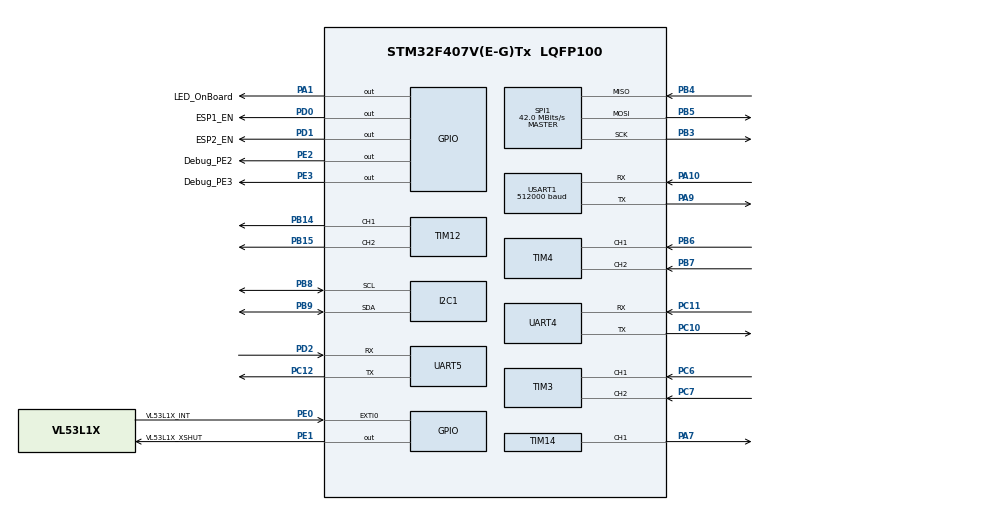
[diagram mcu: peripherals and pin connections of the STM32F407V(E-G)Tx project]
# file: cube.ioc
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ADC1.Channel-1\#ChannelRegularConversion=ADC_CHANNEL_TEMPSENSOR
ADC1.NbrOfConversionFlag=1
ADC1.Rank-1\#ChannelRegularConversion=1
ADC1.SamplingTime-1\#ChannelRegularConversion=ADC_SAMPLETIME_3CYCLES
ADC1.master=1
Dma.Request0=USART1_TX
Dma.USART1_TX.0.Direction=DMA_MEMORY_TO_PERIPH
Dma.USART1_TX.0.FIFOMode=DMA_FIFOMODE_DISABLE
Dma.USART1_TX.0.Instance=DMA2_Stream7
Dma.USART1_TX.0.MemDataAlignment=DMA_MDATAALIGN_BYTE
Dma.USART1_TX.0.MemInc=DMA_MINC_ENABLE
Dma.USART1_TX.0.Mode=DMA_NORMAL
Dma.USART1_TX.0.PeriphDataAlignment=DMA_PDATAALIGN_BYTE
Dma.USART1_TX.0.PeriphInc=DMA_PINC_DISABLE
Dma.USART1_TX.0.Priority=DMA_PRIORITY_LOW
FREERTOS.INCLUDE_pcTaskGetTaskName=1
FREERTOS.INCLUDE_xTaskGetHandle=1
FREERTOS.Tasks01=defaultTask,24,128,StartDefaultTask,Default,NULL
FREERTOS.configCHECK_FOR_STACK_OVERFLOW=2
FREERTOS.configGENERATE_RUN_TIME_STATS=1
FREERTOS.configLIBRARY_MAX_SYSCALL_INTERRUPT_PRIORITY=5
FREERTOS.configTICK_RATE_HZ=100
FREERTOS.configUSE_DAEMON_TASK_STARTUP_HOOK=1
FREERTOS.configUSE_MALLOC_FAILED_HOOK=1
Mcu.Family=STM32F4
Mcu.Name=STM32F407V(E-G)Tx
Mcu.Package=LQFP100
NVIC.DMA2_Stream7_IRQn=true\:10\:0\:true\:false\:true\:true\:false\:true
NVIC.EXTI0_IRQn=true\:10\:0\:true\:false\:true\:true\:true\:true
NVIC.I2C1_ER_IRQn=true\:10\:0\:true\:false\:true\:true\:true\:true
NVIC.I2C1_EV_IRQn=true\:10\:0\:true\:false\:true\:true\:true\:true
NVIC.PriorityGroup=NVIC_PRIORITYGROUP_4
NVIC.SPI1_IRQn=true\:10\:0\:true\:false\:true\:true\:true\:true
NVIC.TIM7_IRQn=true\:8\:0\:true\:false\:true\:true\:true\:true
NVIC.UART4_IRQn=true\:5\:0\:false\:false\:true\:true\:true\:true
NVIC.UART5_IRQn=true\:5\:0\:false\:false\:true\:true\:true\:true
NVIC.USART1_IRQn=true\:10\:0\:true\:false\:true\:true\:true\:true
PA1.GPIO_Label=LED_OnBoard
PA1.Signal=GPIO_Output
PA10.Mode=Asynchronous
PA10.Signal=USART1_RX
PA13.Mode=Serial_Wire
PA13.Signal=SYS_JTMS-SWDIO
PA14.Mode=Serial_Wire
PA14.Signal=SYS_JTCK-SWCLK
PA15.GPIO_Label=SPI_Flash_NCS
PA15.Signal=SPI1_NSS
PA7.Signal=S_TIM14_CH1
PA9.Mode=Asynchronous
PA9.Signal=USART1_TX
PB14.Signal=S_TIM12_CH1
PB15.Signal=S_TIM12_CH2
PB3.Mode=Full_Duplex_Master
PB3.Signal=SPI1_SCK
PB4.Mode=Full_Duplex_Master
PB4.Signal=SPI1_MISO
PB5.Mode=Full_Duplex_Master
PB5.Signal=SPI1_MOSI
PB6.Signal=S_TIM4_CH1
PB7.Signal=S_TIM4_CH2
PB8.Mode=I2C
PB8.Signal=I2C1_SCL
PB9.Mode=I2C
PB9.Signal=I2C1_SDA
PC10.Mode=Asynchronous
PC10.Signal=UART4_TX
PC11.Mode=Asynchronous
PC11.Signal=UART4_RX
PC12.Mode=Asynchronous
PC12.Signal=UART5_TX
PC14-OSC32_IN.Mode=LSE-External-Oscillator
PC14-OSC32_IN.Signal=RCC_OSC32_IN
PC15-OSC32_OUT.Mode=LSE-External-Oscillator
PC15-OSC32_OUT.Signal=RCC_OSC32_OUT
PC6.Signal=S_TIM3_CH1
PC7.Signal=S_TIM3_CH2
PC8.Signal=SDIO_D0
PC9.Signal=SDIO_D1
PD0.GPIO_Label=ESP1_EN
PD0.Signal=GPIO_Output
PD1.GPIO_Label=ESP2_EN
PD1.Signal=GPIO_Output
PD2.Mode=Asynchronous
PD2.Signal=UART5_RX
PE0.GPIO_Label=VL53L1X_INT
PE0.Signal=GPXTI0
PE1.GPIO_Label=VL53L1X_XSHUT
PE1.Signal=GPIO_Output
PE2.GPIO_Label=Debug_PE2
PE2.Signal=GPIO_Output
PE3.GPIO_Label=Debug_PE3
PE3.Signal=GPIO_Output
PH0-OSC_IN.Mode=HSE-External-Oscillator
PH0-OSC_IN.Signal=RCC_OSC_IN
PH1-OSC_OUT.Mode=HSE-External-Oscillator
PH1-OSC_OUT.Signal=RCC_OSC_OUT
ProjectManager.HeapSize=0x200
ProjectManager.StackSize=0x400
ProjectManager.TargetToolchain=Makefile
RCC.48MHZClocksFreq_Value=48000000
RCC.AHBFreq_Value=168000000
RCC.APB1CLKDivider=RCC_HCLK_DIV4
RCC.APB1Freq_Value=42000000
RCC.APB1TimFreq_Value=84000000
RCC.APB2CLKDivider=RCC_HCLK_DIV2
RCC.APB2Freq_Value=84000000
RCC.APB2TimFreq_Value=168000000
RCC.CortexFreq_Value=168000000
RCC.HCLKFreq_Value=168000000
RCC.HSE_VALUE=8000000
RCC.HSI_VALUE=16000000
RCC.PLLM=4
RCC.PLLN=168
RCC.PLLQ=7
RCC.PLLSourceVirtual=RCC_PLLSOURCE_HSE
RCC.SYSCLKFreq_VALUE=168000000
RCC.SYSCLKSource=RCC_SYSCLKSOURCE_PLLCLK
RCC.VCOOutputFreq_Value=336000000
SH.S_TIM12_CH1.0=TIM12_CH1,PWM Generation1 CH1
SH.S_TIM12_CH2.0=TIM12_CH2,PWM Generation2 CH2
SH.S_TIM14_CH1.0=TIM14_CH1,PWM Generation1 CH1
SH.S_TIM3_CH1.0=TIM3_CH1,Encoder_Interface
SH.S_TIM3_CH2.0=TIM3_CH2,Encoder_Interface
SH.S_TIM4_CH1.0=TIM4_CH1,Encoder_Interface
SH.S_TIM4_CH2.0=TIM4_CH2,Encoder_Interface
SPI1.BaudRatePrescaler=SPI_BAUDRATEPRESCALER_2
SPI1.CalculateBaudRate=42.0 MBits/s
SPI1.Direction=SPI_DIRECTION_2LINES
SPI1.Mode=SPI_MODE_MASTER
SPI1.VirtualType=VM_MASTER
TIM12.Channel-PWM\ Generation1\ CH1=TIM_CHANNEL_1
TIM12.Channel-PWM\ Generation2\ CH2=TIM_CHANNEL_2
TIM14.Channel=TIM_CHANNEL_1
TIM3.EncoderMode=TIM_ENCODERMODE_TI12
TIM4.EncoderMode=TIM_ENCODERMODE_TI12
TIM7.Prescaler=0
UART4.VirtualMode=Asynchronous
UART5.VirtualMode=Asynchronous
USART1.BaudRate=512000
USART1.VirtualMode=VM_ASYNC
VP_ADC1_TempSens_Input.Mode=IN-TempSens
VP_ADC1_Vbat_Input.Mode=IN-Vbat
VP_ADC1_Vref_Input.Mode=IN-Vrefint
VP_FREERTOS_VS_CMSIS_V2.Mode=CMSIS_V2
VP_TIM12_VS_ClockSourceINT.Mode=Internal
VP_TIM14_VS_ClockSourceINT.Mode=Enable_Timer
VP_TIM7_VS_ClockSourceINT.Mode=Enable_Timer
board=custom

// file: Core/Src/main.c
/* USER CODE BEGIN Header */
/**
  ******************************************************************************
  * @file           : main.c
  * @brief          : Main program body
  ******************************************************************************
  * @attention
  *
  * <h2><center>&copy; Copyright (c) 2019 STMicroelectronics.
  * All rights reserved.</center></h2>
  *
  * This software component is licensed by ST under Ultimate Liberty license
  * SLA0044, the "License"; You may not use this file except in compliance with
  * the License. You may obtain a copy of the License at:
  *                             www.st.com/SLA0044
  *
  ******************************************************************************
  */
/* USER CODE END Header */

#include "main.h"
#include "cmsis_os.h"
#include "adc.h"
#include "dma.h"
#include "i2c.h"
#include "spi.h"
#include "tim.h"
#include "usart.h"
#include "gpio.h"

void SystemClock_Config(void);
void MX_FREERTOS_Init(void);

/* USER CODE BEGIN 0 */
#define main __unused_function_jrl23j4lk3n4
/* USER CODE END 0 */

int main(void)
{
  /* USER CODE BEGIN 1 */
#undef main
  /* USER CODE END 1 */

  /* MCU Configuration--------------------------------------------------------*/

  /* Reset of all peripherals, Initializes the Flash interface and the Systick. */

  LL_APB2_GRP1_EnableClock(LL_APB2_GRP1_PERIPH_SYSCFG);
  LL_APB1_GRP1_EnableClock(LL_APB1_GRP1_PERIPH_PWR);

  NVIC_SetPriorityGrouping(NVIC_PRIORITYGROUP_4);

  /* System interrupt init*/
  /* PendSV_IRQn interrupt configuration */
  NVIC_SetPriority(PendSV_IRQn, NVIC_EncodePriority(NVIC_GetPriorityGrouping(),15, 0));
  /* SysTick_IRQn interrupt configuration */
  NVIC_SetPriority(SysTick_IRQn, NVIC_EncodePriority(NVIC_GetPriorityGrouping(),15, 0));

  /* Configure the system clock */
  SystemClock_Config();

  /* Initialize all configured peripherals */
  MX_GPIO_Init();
  MX_ADC1_Init();
  MX_SPI1_Init();
  MX_DMA_Init();
  MX_USART1_UART_Init();
  MX_I2C1_Init();
  MX_TIM3_Init();
  MX_TIM4_Init();
  MX_TIM7_Init();
  MX_TIM12_Init();
  MX_TIM14_Init();
  MX_UART4_Init();
  MX_UART5_Init();

  /* Call init function for freertos objects (in freertos.c) */
  MX_FREERTOS_Init();

  /* Start scheduler */
  osKernelStart();

  /* We should never get here as control is now taken by the scheduler */

  /* Infinite loop */
  while (1)
  {

  }
}

void SystemClock_Config(void)
{
  LL_FLASH_SetLatency(LL_FLASH_LATENCY_5);

  if(LL_FLASH_GetLatency() != LL_FLASH_LATENCY_5)
  {
  Error_Handler();
  }
  LL_PWR_SetRegulVoltageScaling(LL_PWR_REGU_VOLTAGE_SCALE1);
  LL_RCC_HSE_Enable();

   /* Wait till HSE is ready */
  while(LL_RCC_HSE_IsReady() != 1)
  {

  }
  LL_RCC_PLL_ConfigDomain_SYS(LL_RCC_PLLSOURCE_HSE, LL_RCC_PLLM_DIV_4, 168, LL_RCC_PLLP_DIV_2);
  LL_RCC_PLL_Enable();

   /* Wait till PLL is ready */
  while(LL_RCC_PLL_IsReady() != 1)
  {

  }
  LL_RCC_SetAHBPrescaler(LL_RCC_SYSCLK_DIV_1);
  LL_RCC_SetAPB1Prescaler(LL_RCC_APB1_DIV_4);
  LL_RCC_SetAPB2Prescaler(LL_RCC_APB2_DIV_2);
  LL_RCC_SetSysClkSource(LL_RCC_SYS_CLKSOURCE_PLL);

   /* Wait till System clock is ready */
  while(LL_RCC_GetSysClkSource() != LL_RCC_SYS_CLKSOURCE_STATUS_PLL)
  {

  }
  LL_Init1msTick(168000000);
  LL_SYSTICK_SetClkSource(LL_SYSTICK_CLKSOURCE_HCLK);
  LL_SetSystemCoreClock(168000000);
}

/* USER CODE BEGIN 4 */
#define Error_Handler __disabled_Error_Handler
/* USER CODE END 4 */

void Error_Handler(void)
{
  /* USER CODE BEGIN Error_Handler_Debug */
  /* User can add his own implementation to report the HAL error return state */
#undef Error_Handler
  /* USER CODE END Error_Handler_Debug */
}

/************************ (C) COPYRIGHT STMicroelectronics *****END OF FILE****/

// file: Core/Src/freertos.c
/* USER CODE BEGIN Header */
/**
  ******************************************************************************
  * File Name          : freertos.c
  * Description        : Code for freertos applications
  ******************************************************************************
  * @attention
  *
  * <h2><center>&copy; Copyright (c) 2019 STMicroelectronics.
  * All rights reserved.</center></h2>
  *
  * This software component is licensed by ST under Ultimate Liberty license
  * SLA0044, the "License"; You may not use this file except in compliance with
  * the License. You may obtain a copy of the License at:
  *                             www.st.com/SLA0044
  *
  ******************************************************************************
  */
/* USER CODE END Header */

#include "FreeRTOS.h"
#include "task.h"
#include "main.h"
#include "cmsis_os.h"

osThreadId_t defaultTaskHandle;

void StartDefaultTask(void *argument);

void MX_FREERTOS_Init(void); /* (MISRA C 2004 rule 8.1) */

/* Hook prototypes */
void configureTimerForRunTimeStats(void);
unsigned long getRunTimeCounterValue(void);
void vApplicationStackOverflowHook(xTaskHandle xTask, signed char *pcTaskName);
void vApplicationMallocFailedHook(void);
void vApplicationDaemonTaskStartupHook(void);

/* USER CODE BEGIN 1 */
/* Functions needed when configGENERATE_RUN_TIME_STATS is on */
__weak void configureTimerForRunTimeStats(void)
{

}

__weak unsigned long getRunTimeCounterValue(void)
{
return 0;
}
/* USER CODE END 1 */

/* USER CODE BEGIN 4 */
__weak void vApplicationStackOverflowHook(xTaskHandle xTask, signed char *pcTaskName)
{
   /* Run time stack overflow checking is performed if
   configCHECK_FOR_STACK_OVERFLOW is defined to 1 or 2. This hook function is
   called if a stack overflow is detected. */
}
/* USER CODE END 4 */

/* USER CODE BEGIN 5 */
__weak void vApplicationMallocFailedHook(void)
{
   /* vApplicationMallocFailedHook() will only be called if
   configUSE_MALLOC_FAILED_HOOK is set to 1 in FreeRTOSConfig.h. It is a hook
   function that will get called if a call to pvPortMalloc() fails.
   pvPortMalloc() is called internally by the kernel whenever a task, queue,
   timer or semaphore is created. It is also called by various parts of the
   demo application. If heap_1.c or heap_2.c are used, then the size of the
   heap available to pvPortMalloc() is defined by configTOTAL_HEAP_SIZE in
   FreeRTOSConfig.h, and the xPortGetFreeHeapSize() API function can be used
   to query the size of free heap space that remains (although it does not
   provide information on how the remaining heap might be fragmented). */
}
/* USER CODE END 5 */

/* USER CODE BEGIN DAEMON_TASK_STARTUP_HOOK */
void vApplicationDaemonTaskStartupHook(void)
{
}
/* USER CODE END DAEMON_TASK_STARTUP_HOOK */

void MX_FREERTOS_Init(void) {
osKernelInitialize();

  /* Create the thread(s) */
  /* definition and creation of defaultTask */
  const osThreadAttr_t defaultTask_attributes = {
    .name = "defaultTask",
    .priority = (osPriority_t) osPriorityNormal,
    .stack_size = 128
  };
  defaultTaskHandle = osThreadNew(StartDefaultTask, NULL, &defaultTask_attributes);

}

void StartDefaultTask(void *argument)
{
  for(;;)
  {
    osDelay(1);
  }
}

/************************ (C) COPYRIGHT STMicroelectronics *****END OF FILE****/
